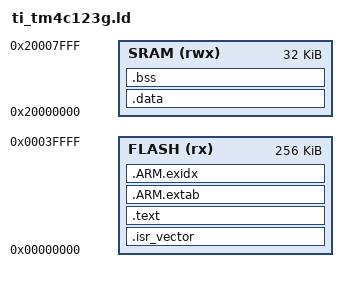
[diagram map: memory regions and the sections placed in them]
/******************************************************************************
 *
 * freertos_demo.ld - Linker configuration file for freertos_demo.
 *
 * Copyright (c) 2012-2013 Texas Instruments Incorporated.  All rights reserved.
 * Software License Agreement
 * 
 * Texas Instruments (TI) is supplying this software for use solely and
 * exclusively on TI's microcontroller products. The software is owned by
 * TI and/or its suppliers, and is protected under applicable copyright
 * laws. You may not combine this software with "viral" open-source
 * software in order to form a larger program.
 * 
 * THIS SOFTWARE IS PROVIDED "AS IS" AND WITH ALL FAULTS.
 * NO WARRANTIES, WHETHER EXPRESS, IMPLIED OR STATUTORY, INCLUDING, BUT
 * NOT LIMITED TO, IMPLIED WARRANTIES OF MERCHANTABILITY AND FITNESS FOR
 * A PARTICULAR PURPOSE APPLY TO THIS SOFTWARE. TI SHALL NOT, UNDER ANY
 * CIRCUMSTANCES, BE LIABLE FOR SPECIAL, INCIDENTAL, OR CONSEQUENTIAL
 * DAMAGES, FOR ANY REASON WHATSOEVER.
 * 
 * This is part of revision 2.0.1.11577 of the EK-TM4C123GXL Firmware Package.
 *
 *****************************************************************************/

MEMORY
{
    FLASH (rx) : ORIGIN = 0x00000000, LENGTH = 256K
    SRAM (rwx) : ORIGIN = 0x20000000, LENGTH = 32K
}

stack_size = 1024; 

SECTIONS
{
    /* The startup code goes first into FLASH */
    .isr_vector :
    {
        . = ALIGN(4);
        _isr_vector = .;     /* define isr_vector start address */
        KEEP(*(.isr_vector)) /* Startup code */
        . = ALIGN(4);
    } >FLASH

    .text :
    {
        . = ALIGN(4);
        *(.text)           /* .text sections (code) */
        *(.text*)          /* .text* sections (code) */
        *(.rodata)         /* .rodata sections (constants, strings, etc.) */
        *(.rodata*)        /* .rodata* sections (constants, strings, etc.) */
        *(.glue_7)         /* glue arm to thumb code */
        *(.glue_7t)        /* glue thumb to arm code */
        *(.eh_frame)

        KEEP (*(.init))
        KEEP (*(.fini))

        . = ALIGN(4);
        _etext = .;        /* define a global symbols at end of code */
    } >FLASH


    /*
    ** C++ only
    */

    .ARM.extab   : { 
        *(.ARM.extab* .gnu.linkonce.armextab.*) 
    } >FLASH



    /*
    ** used only for C++ exception handling
    */
    PROVIDE_HIDDEN (__exidx_start = .);
    .ARM.exidx   : { 
        __exidx_start = .;
        *(.ARM.exidx* .gnu.linkonce.armexidx.*)
        __exidx_end = .;
    } >FLASH
    PROVIDE_HIDDEN (__exidx_end = .);
    

    _begin_data = .;

    . = ALIGN(4);
    .data : AT(_begin_data)  
    {
        . = ALIGN(4);
        _data = .;
        *(vtable)
        *(.data*)
        . = ALIGN(4);
        _edata = .;
    } > SRAM

    

    . = ALIGN(4);
    .bss :
    {
        _bss = .;
        _sbss = .;  
        __bss_start__ = _sbss;
        *(.bss)
        *(.bss*)
        *(COMMON)

        . = ALIGN(4);
        _ebss = .;  
        __bss_end__ = _ebss;
    } >SRAM


    . = ALIGN(4);
    _end = .;
    __end = _end;
    PROVIDE(end = .);


}
